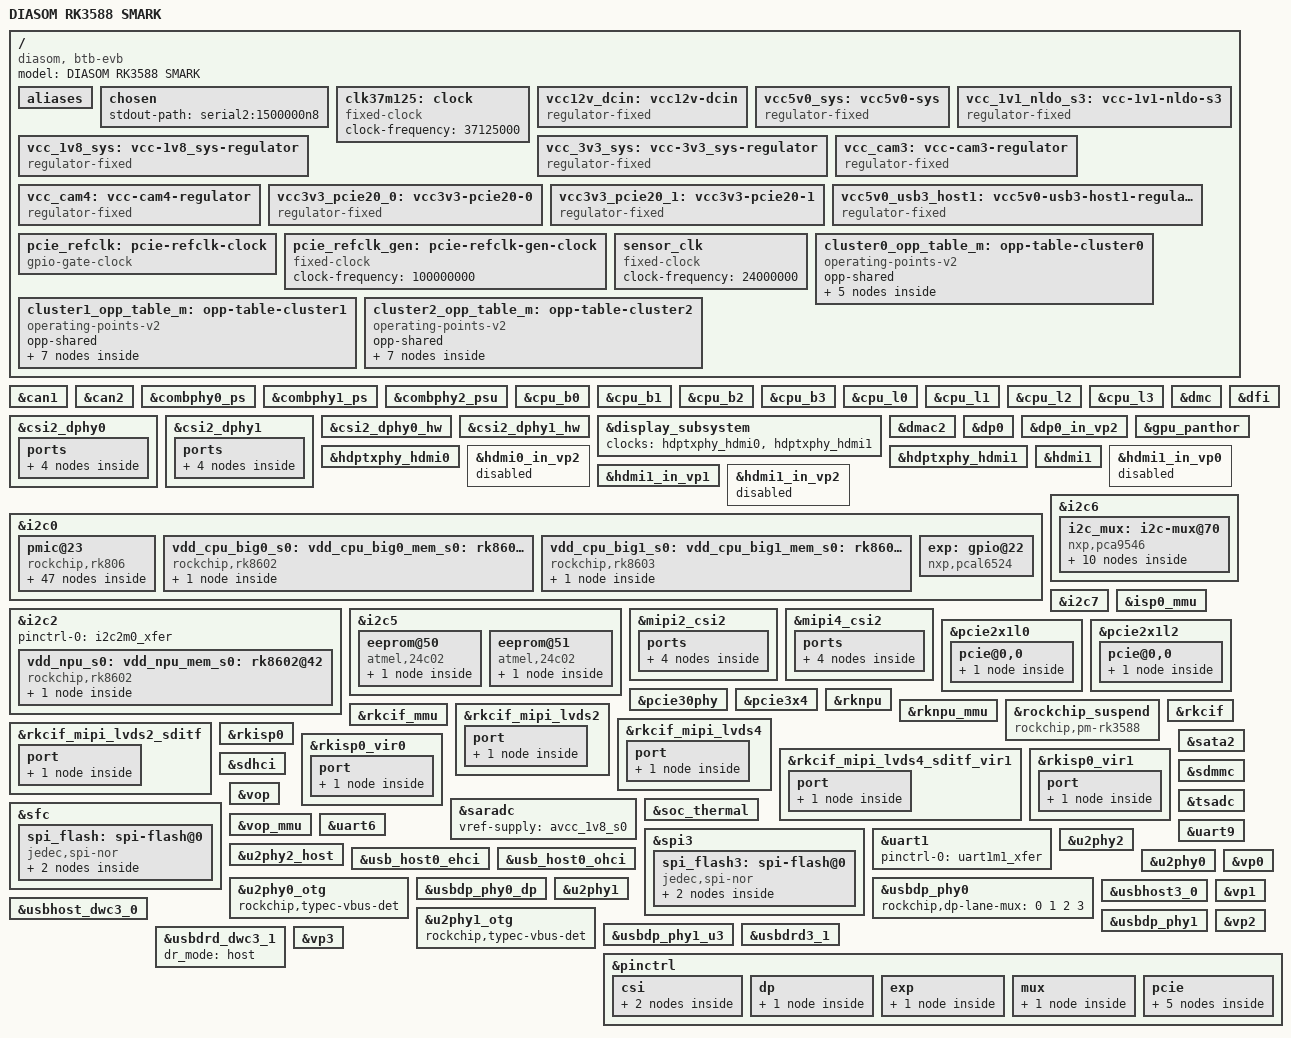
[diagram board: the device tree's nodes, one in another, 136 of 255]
// SPDX-License-Identifier: (GPL-2.0+ OR MIT)
/*
 * Copyright (c) 2022 Rockchip Electronics Co., Ltd.
 * Copyright (c) 2022 Radxa Limited
 *
 */

/dts-v1/;

#include <dt-bindings/gpio/gpio.h>
#include <dt-bindings/leds/common.h>
#include <dt-bindings/pwm/pwm.h>
#include <dt-bindings/pinctrl/rockchip.h>
#include <dt-bindings/input/rk-input.h>
#include <dt-bindings/display/drm_mipi_dsi.h>
#include <dt-bindings/display/media-bus-format.h>
#include <dt-bindings/display/rockchip_vop.h>
#include <dt-bindings/sensor-dev.h>
#include "dt-bindings/usb/pd.h"
#include "rk3588.dtsi"
#include "rk3588-linux.dtsi"

/ {
	model = "DIASOM RK3588 SMARK";
	compatible = "diasom, btb-evb", "rockchip,rk3588";

	aliases {
		ethernet0 = &ethernet0;
		ethernet1 = &ethernet1;
		i2c9 = &i2c9;
		i2c10 = &i2c10;
		i2c11 = &i2c11;
		i2c12 = &i2c12;
		mmc0 = &sdhci;
		mmc1 = &sdmmc;
	};

	chosen {
		stdout-path = "serial2:1500000n8";
	};

	clk37m125: clock {
		compatible = "fixed-clock";
		#clock-cells = <0>;
		clock-frequency = <37125000>;
	};

	vcc12v_dcin: vcc12v-dcin {
		compatible = "regulator-fixed";
		regulator-name = "vcc12v_dcin";
		regulator-always-on;
		regulator-boot-on;
		regulator-min-microvolt = <12000000>;
		regulator-max-microvolt = <12000000>;
	};

	vcc5v0_sys: vcc5v0-sys {
		compatible = "regulator-fixed";
		regulator-name = "vcc5v0_sys";
		regulator-always-on;
		regulator-boot-on;
		regulator-min-microvolt = <5000000>;
		regulator-max-microvolt = <5000000>;
		vin-supply = <&vcc12v_dcin>;
	};

	vcc_1v1_nldo_s3: vcc-1v1-nldo-s3 {
		compatible = "regulator-fixed";
		regulator-name = "vcc_1v1_nldo_s3";
		regulator-always-on;
		regulator-boot-on;
		regulator-min-microvolt = <1100000>;
		regulator-max-microvolt = <1100000>;
		vin-supply = <&vcc5v0_sys>;
	};

	vcc_1v8_sys: vcc-1v8_sys-regulator {
		compatible = "regulator-fixed";
		regulator-name = "vcc_1v8_sys";
		regulator-always-on;
		regulator-boot-on;
		regulator-min-microvolt = <1800000>;
		regulator-max-microvolt = <1800000>;
		vin-supply = <&vcc5v0_sys>;
	};

	vcc_3v3_sys: vcc-3v3_sys-regulator {
		compatible = "regulator-fixed";
		regulator-name = "vcc_3v3_sys";
		regulator-always-on;
		regulator-boot-on;
		regulator-min-microvolt = <3300000>;
		regulator-max-microvolt = <3300000>;
		vin-supply = <&vcc12v_dcin>;
	};

	vcc_cam3: vcc-cam3-regulator {
		pinctrl-names = "default";
		pinctrl-0 = <&cam3_pwr>;
		compatible = "regulator-fixed";
		regulator-boot-on;
		regulator-always-on;
		enable-active-high;
		gpio = <&gpio3 RK_PC1 GPIO_ACTIVE_HIGH>;
		regulator-name = "vcc_cam3";
		startup-delay-us = <250000>;
	};
	
	vcc_cam4: vcc-cam4-regulator {
		pinctrl-names = "default";
		pinctrl-0 = <&cam4_pwr>;
		compatible = "regulator-fixed";
		regulator-boot-on;
		regulator-always-on;
		enable-active-high;
		gpio = <&gpio3 RK_PC2 GPIO_ACTIVE_HIGH>;
		regulator-name = "vcc_cam4";
		startup-delay-us = <250000>;
	};

	vcc3v3_pcie20_0: vcc3v3-pcie20-0 {
		pinctrl-names = "default";
		pinctrl-0 = <&pcie20_0_vcc_pins>;
		compatible = "regulator-fixed";
		regulator-name = "vcc3v3_pcie20_0";
		regulator-min-microvolt = <3300000>;
		regulator-max-microvolt = <3300000>;
		enable-active-high;
		gpios = <&gpio1 RK_PC0 GPIO_ACTIVE_HIGH>;
		startup-delay-us = <5000>;
		vin-supply = <&vcc_3v3_sys>;
	};

	vcc3v3_pcie20_1: vcc3v3-pcie20-1 {
		pinctrl-names = "default";
		pinctrl-0 = <&pcie20_1_vcc_pins>;
		compatible = "regulator-fixed";
		regulator-name = "vcc3v3_pcie20_1";
		regulator-min-microvolt = <3300000>;
		regulator-max-microvolt = <3300000>;
		enable-active-high;
		regulator-always-on;
		regulator-boot-on;
		gpios = <&gpio1 RK_PC1 GPIO_ACTIVE_HIGH>;
		startup-delay-us = <5000>;
		vin-supply = <&vcc_3v3_sys>;
	};

	vcc5v0_usb3_host1: vcc5v0-usb3-host1-regulator {
		compatible = "regulator-fixed";
		regulator-name = "vcc5v0_usb3_host1";
		regulator-boot-on;
		regulator-always-on;
		regulator-min-microvolt = <5000000>;
		regulator-max-microvolt = <5000000>;
		vin-supply = <&vcc12v_dcin>;
	};

	pcie_refclk: pcie-refclk-clock {
		pinctrl-names = "default";
		pinctrl-0 = <&pcie30_clk_pins>;
		compatible = "gpio-gate-clock";
		clocks = <&pcie_refclk_gen>;
		#clock-cells = <0>;
		enable-gpios = <&gpio4 RK_PA5 GPIO_ACTIVE_HIGH>;
	};

	pcie_refclk_gen: pcie-refclk-gen-clock {
		compatible = "fixed-clock";
		#clock-cells = <0>;
		clock-frequency = <100000000>;
	};

	sensor_clk: sensor_clk {
        compatible = "fixed-clock";
        #clock-cells = <0>;
        clock-frequency = <24000000>;
    };

	cluster0_opp_table_m: opp-table-cluster0 {
		compatible = "operating-points-v2";
		opp-shared;

		opp-1008000000 {
			opp-hz = /bits/ 64 <1008000000>;
			opp-microvolt = <675000 675000 950000>;
			clock-latency-ns = <40000>;
		};
		opp-1200000000 {
			opp-hz = /bits/ 64 <1200000000>;
			opp-microvolt = <712500 712500 950000>;
			clock-latency-ns = <40000>;
		};
		opp-1416000000 {
			opp-hz = /bits/ 64 <1416000000>;
			opp-microvolt = <762500 762500 950000>;
			clock-latency-ns = <40000>;
			opp-suspend;
		};
		opp-1608000000 {
			opp-hz = /bits/ 64 <1608000000>;
			opp-microvolt = <850000 850000 950000>;
			clock-latency-ns = <40000>;
		};
		opp-1800000000 {
			opp-hz = /bits/ 64 <1800000000>;
			opp-microvolt = <950000 950000 950000>;
			clock-latency-ns = <40000>;
		};
	};

	cluster1_opp_table_m: opp-table-cluster1 {
		compatible = "operating-points-v2";
		opp-shared;

		opp-1200000000 {
			opp-hz = /bits/ 64 <1200000000>;
			opp-microvolt = <675000 675000 1000000>;
			clock-latency-ns = <40000>;
		};
		opp-1416000000 {
			opp-hz = /bits/ 64 <1416000000>;
			opp-microvolt = <725000 725000 1000000>;
			clock-latency-ns = <40000>;
		};
		opp-1608000000 {
			opp-hz = /bits/ 64 <1608000000>;
			opp-microvolt = <762500 762500 1000000>;
			clock-latency-ns = <40000>;
		};
		opp-1800000000 {
			opp-hz = /bits/ 64 <1800000000>;
			opp-microvolt = <850000 850000 1000000>;
			clock-latency-ns = <40000>;
		};
		opp-2016000000 {
			opp-hz = /bits/ 64 <2016000000>;
			opp-microvolt = <925000 925000 1000000>;
			clock-latency-ns = <40000>;
		};
		opp-2208000000 {
			opp-hz = /bits/ 64 <2208000000>;
			opp-microvolt = <987500 987500 1000000>;
			clock-latency-ns = <40000>;
		};
		opp-2400000000 {
			opp-hz = /bits/ 64 <2400000000>;
			opp-microvolt = <1000000 1000000 1000000>;
			clock-latency-ns = <40000>;
		};
	};

	cluster2_opp_table_m: opp-table-cluster2 {
		compatible = "operating-points-v2";
		opp-shared;

		opp-1200000000 {
			opp-hz = /bits/ 64 <1200000000>;
			opp-microvolt = <675000 675000 1000000>;
			clock-latency-ns = <40000>;
		};
		opp-1416000000 {
			opp-hz = /bits/ 64 <1416000000>;
			opp-microvolt = <725000 725000 1000000>;
			clock-latency-ns = <40000>;
		};
		opp-1608000000 {
			opp-hz = /bits/ 64 <1608000000>;
			opp-microvolt = <762500 762500 1000000>;
			clock-latency-ns = <40000>;
		};
		opp-1800000000 {
			opp-hz = /bits/ 64 <1800000000>;
			opp-microvolt = <850000 850000 1000000>;
			clock-latency-ns = <40000>;
		};
		opp-2016000000 {
			opp-hz = /bits/ 64 <2016000000>;
			opp-microvolt = <925000 925000 1000000>;
			clock-latency-ns = <40000>;
		};
		opp-2208000000 {
			opp-hz = /bits/ 64 <2208000000>;
			opp-microvolt = <987500 987500 1000000>;
			clock-latency-ns = <40000>;
		};
		opp-2400000000 {
			opp-hz = /bits/ 64 <2400000000>;
			opp-microvolt = <1000000 1000000 1000000>;
			clock-latency-ns = <40000>;
		};
	};
};

&can1 {
	status = "okay";
	pinctrl-names = "default";
	pinctrl-0 = <&can1m1_pins>;
	assigned-clocks = <&cru CLK_CAN1>;
	assigned-clock-rates = <200000000>;
};

&can2 {
	status = "okay";
	pinctrl-names = "default";
	pinctrl-0 = <&can2m1_pins>;
	assigned-clocks = <&cru CLK_CAN2>;
	assigned-clock-rates = <200000000>;
};

&combphy0_ps {
	/* pcie2x1l2 (PCIE20_0) */
	status = "okay";
};

&combphy1_ps {
	/* pcie2x1l0 (PCIE20_1) */
	status = "okay";
};

&combphy2_psu {
	status = "okay";
};

&cpu_b0 {
	cpu-supply = <&vdd_cpu_big0_s0>;
	// mem-supply = <&vdd_cpu_big0_s0>;
	operating-points-v2 = <&cluster1_opp_table_m>;
};

&cpu_b1 {
	cpu-supply = <&vdd_cpu_big0_s0>;
	// mem-supply = <&vdd_cpu_big0_s0>;
	operating-points-v2 = <&cluster1_opp_table_m>;
};

&cpu_b2 {
	cpu-supply = <&vdd_cpu_big1_s0>;
	// mem-supply = <&vdd_cpu_big1_s0>;
	operating-points-v2 = <&cluster2_opp_table_m>;
};

&cpu_b3 {
	cpu-supply = <&vdd_cpu_big1_s0>;
	// mem-supply = <&vdd_cpu_big1_s0>;
	operating-points-v2 = <&cluster2_opp_table_m>;
};

&cpu_l0 {
	cpu-supply = <&vdd_cpu_lit_s0>;
	// mem-supply = <&vdd_cpu_lit_s0>;
	operating-points-v2 = <&cluster0_opp_table_m>;
};

&cpu_l1 {
	cpu-supply = <&vdd_cpu_lit_s0>;
	// mem-supply = <&vdd_cpu_lit_s0>;
	operating-points-v2 = <&cluster0_opp_table_m>;
};

&cpu_l2 {
	cpu-supply = <&vdd_cpu_lit_s0>;
	// mem-supply = <&vdd_cpu_lit_s0>;
	operating-points-v2 = <&cluster0_opp_table_m>;
};

&cpu_l3 {
	cpu-supply = <&vdd_cpu_lit_s0>;
	// mem-supply = <&vdd_cpu_lit_s0>;
	operating-points-v2 = <&cluster0_opp_table_m>;
};

&csi2_dphy0 {
	status = "okay";

	ports {
		#address-cells = <1>;
		#size-cells = <0>;

		port@0 {
			reg = <0>;
			#address-cells = <1>;
			#size-cells = <0>;

			mipidphy0_in_ucam0: endpoint@1 {
				reg = <1>;
				remote-endpoint = <&imx415_i2c11_out>;
				data-lanes = <1 2 3 4>;
			};
		};

		port@1 {
			reg = <1>;
			#address-cells = <1>;
			#size-cells = <0>;

			csidphy0_out: endpoint@0 {
				reg = <0>;
				remote-endpoint = <&mipi2_csi2_input>;
			};
		};
	};
};


&csi2_dphy1 {
	status = "okay";

	ports {
		#address-cells = <1>;
		#size-cells = <0>;

		port@0 {
			reg = <0>;
			#address-cells = <1>;
			#size-cells = <0>;

			mipidphy1_in_ucam1: endpoint@1 {
				reg = <1>;
				remote-endpoint = <&imx415_i2c12_out>;
				data-lanes = <1 2 3 4>;
			};
		};

		port@1 {
			reg = <1>;
			#address-cells = <1>;
			#size-cells = <0>;

			csidphy1_out: endpoint@0 {
				reg = <0>;
				remote-endpoint = <&mipi4_csi2_input>;
			};
		};
	};
};

&csi2_dphy0_hw {
	status = "okay";
};

&csi2_dphy1_hw {
	status = "okay";
};

&display_subsystem {
	clocks = <&hdptxphy_hdmi0>, <&hdptxphy_hdmi1>;
	clock-names = "hdmi0_phy_pll", "hdmi1_phy_pll";
};

&dmc {
	center-supply = <&vdd_ddr_s0>;
	mem-supply = <&vdd_log_s0>;
	status = "okay";
};

&dfi {
	status = "okay";
};

&dmac2 {
	status = "okay";
};

&dp0 {
	pinctrl-names = "default";
	pinctrl-0 = <&dp0_tx1_hpd>;
	hpd-gpios = <&gpio2 RK_PC1 GPIO_ACTIVE_HIGH>;
	status = "okay";
};

&dp0_in_vp2 {
	status = "okay";
};

&gpu_panthor {
	mali-supply = <&vdd_gpu_s0>;
	mem-supply = <&vdd_gpu_mem_s0>;
	status = "okay";
};

&hdptxphy_hdmi0 {
	status = "okay";
};

&hdptxphy_hdmi1 {
	status = "okay";
};

&hdmi0_in_vp2 {
	status = "disabled";
};

&hdmi1 {
	status = "okay";
	pinctrl-names = "default";
	pinctrl-0 = <&hdmim0_tx1_hpd>;
    cec-enable = "true";
};

&hdmi1_in_vp0 {
	status = "disabled";
};

&hdmi1_in_vp1 {
	status = "okay";
};

&hdmi1_in_vp2 {
	status = "disabled";
};

&i2c0 {
	status = "okay";
	pinctrl-names = "default";
	pinctrl-0 = <&i2c0m2_xfer>;
	clock-frequency = <100000>;

	pmic@23 {
		compatible = "rockchip,rk806";
		reg = <0x23>;
		interrupt-parent = <&gpio0>;
		interrupts = <7 IRQ_TYPE_LEVEL_LOW>;
		pinctrl-names = "default", "pmic-power-off";
		pinctrl-0 = <&pmic_pins>, <&rk806_dvs1_null>, <&rk806_dvs2_null>, <&rk806_dvs3_null>;
		pinctrl-1 = <&rk806_dvs1_pwrdn>;

		/* 2800mv-3500mv */
		low_voltage_threshold = <3000>;
		/* 2700mv-3400mv */
		shutdown_voltage_threshold = <2700>;
		/* 140 160 */
		shutdown_temperture_threshold = <160>;
		hotdie_temperture_threshold = <115>;

		shutdown-sequence = <2 2 2 0 2 0 2 1 1 2
					2 2 2 2 2
					1 0 0 0 0 2>;

		/* low power forced shutdown sequence */
		vb-shutdown-sequence = <2 2 2 0 2 0 2 0 0 2
					2 2 2 2 2
					0 0 0 0 0 2>;

		pwron-on-time-500ms;
		/* 0: restart PMU;
		 * 1: reset all the power off reset registers,
		 *    forcing the state to switch to ACTIVE mode;
		 * 2: Reset all the power off reset registers,
		 *    forcing the state to switch to ACTIVE mode,
		 *    and simultaneously pull down the RESETB PIN for 5mS before releasing
		 */
		pmic-reset-func = <1>;

		buck5-feedback-disable;

		vcc1-supply = <&vcc5v0_sys>;
		vcc2-supply = <&vcc5v0_sys>;
		vcc3-supply = <&vcc5v0_sys>;
		vcc4-supply = <&vcc5v0_sys>;
		vcc5-supply = <&vcc5v0_sys>;
		vcc6-supply = <&vcc5v0_sys>;
		vcc7-supply = <&vcc5v0_sys>;
		vcc8-supply = <&vcc5v0_sys>;
		vcc9-supply = <&vcc5v0_sys>;
		vcc10-supply = <&vcc5v0_sys>;
		vcc11-supply = <&vcc_2v0_pldo_s3>;
		vcc12-supply = <&vcc5v0_sys>;
		vcc13-supply = <&vcc_1v1_nldo_s3>;
		vcc14-supply = <&vcc_1v1_nldo_s3>;
		vcca-supply = <&vcc5v0_sys>;

		rk806_dvs1_null: dvs1-null-pins {
			pins = "gpio_pwrctrl1";
			function = "pin_fun0";
		};

		rk806_dvs2_null: dvs2-null-pins {
			pins = "gpio_pwrctrl2";
			function = "pin_fun0";
		};

		rk806_dvs3_null: dvs3-null-pins {
			pins = "gpio_pwrctrl3";
			function = "pin_fun0";
		};

		rk806_dvs1_pwrdn: rk806_dvs1_pwrdn {
			pins = "gpio_pwrctrl1";
			function = "pin_fun2";
		};

		regulators {
			vdd_gpu_s0: vdd_gpu_mem_s0: DCDC_REG1 {
				regulator-boot-on;
				regulator-min-microvolt = <550000>;
				regulator-max-microvolt = <950000>;
				regulator-ramp-delay = <12500>;
				regulator-name = "vdd_gpu_s0";
				regulator-enable-ramp-delay = <400>;
				regulator-state-mem {
					regulator-off-in-suspend;
				};
			};

			vdd_cpu_lit_s0: vdd_cpu_lit_mem_s0: DCDC_REG2 {
				regulator-always-on;
				regulator-boot-on;
				regulator-init-microvolt = <800000>;
				regulator-min-microvolt = <550000>;
				regulator-max-microvolt = <950000>;
				regulator-ramp-delay = <12500>;
				regulator-name = "vdd_cpu_lit_s0";
				regulator-state-mem {
					regulator-off-in-suspend;
				};
			};

			vdd_log_s0: DCDC_REG3 {
				regulator-always-on;
				regulator-boot-on;
				regulator-min-microvolt = <675000>;
				regulator-max-microvolt = <800000>;
				regulator-ramp-delay = <12500>;
				regulator-name = "vdd_log_s0";
				regulator-state-mem {
					regulator-off-in-suspend;
					regulator-suspend-microvolt = <750000>;
				};
			};

			vdd_vdenc_s0: vdd_vdenc_mem_s0: DCDC_REG4 {
				regulator-always-on;
				regulator-boot-on;
				regulator-min-microvolt = <550000>;
				regulator-max-microvolt = <950000>;
				regulator-init-microvolt = <750000>;
				regulator-ramp-delay = <12500>;
				regulator-name = "vdd_vdenc_s0";
				regulator-state-mem {
					regulator-off-in-suspend;
				};
			};

			vdd_ddr_s0: DCDC_REG5 {
				regulator-always-on;
				regulator-boot-on;
				regulator-min-microvolt = <675000>;
				regulator-max-microvolt = <900000>;
				regulator-ramp-delay = <12500>;
				regulator-name = "vdd_ddr_s0";
				regulator-state-mem {
					regulator-off-in-suspend;
					regulator-suspend-microvolt = <850000>;
				};
			};

			vdd2_ddr_s3: DCDC_REG6 {
				regulator-always-on;
				regulator-boot-on;
				regulator-name = "vdd2_ddr_s3";
				regulator-state-mem {
					regulator-on-in-suspend;
				};
			};

			vcc_2v0_pldo_s3: DCDC_REG7 {
				regulator-always-on;
				regulator-boot-on;
				regulator-min-microvolt = <2000000>;
				regulator-max-microvolt = <2000000>;
				regulator-name = "vdd_2v0_pldo_s3";
				regulator-state-mem {
					regulator-on-in-suspend;
					regulator-suspend-microvolt = <2000000>;
				};
			};

			vcc_3v3_s3: DCDC_REG8 {
				regulator-always-on;
				regulator-boot-on;
				regulator-min-microvolt = <3300000>;
				regulator-max-microvolt = <3300000>;
				regulator-name = "vcc_3v3_s3";
				regulator-state-mem {
					regulator-on-in-suspend;
					regulator-suspend-microvolt = <3300000>;
				};
			};

			vddq_ddr_s0: DCDC_REG9 {
				regulator-always-on;
				regulator-boot-on;
				regulator-name = "vddq_ddr_s0";
				regulator-state-mem {
					regulator-off-in-suspend;
				};
			};

			vcc_1v8_s3: DCDC_REG10 {
				regulator-always-on;
				regulator-boot-on;
				regulator-min-microvolt = <1800000>;
				regulator-max-microvolt = <1800000>;
				regulator-name = "vcc_1v8_s3";
				regulator-state-mem {
					regulator-on-in-suspend;
					regulator-suspend-microvolt = <1800000>;
				};
			};

			avcc_1v8_s0: PLDO_REG1 {
				regulator-always-on;
				regulator-boot-on;
				regulator-min-microvolt = <1800000>;
				regulator-max-microvolt = <1800000>;
				regulator-name = "avcc_1v8_s0";
				regulator-state-mem {
					regulator-off-in-suspend;
				};
			};

			vcc_1v8_s0: PLDO_REG2 {
				regulator-always-on;
				regulator-boot-on;
				regulator-min-microvolt = <1800000>;
				regulator-max-microvolt = <1800000>;
				regulator-name = "vcc_1v8_s0";
				regulator-state-mem {
					regulator-off-in-suspend;
					regulator-suspend-microvolt = <1800000>;
				};
			};

			avdd_1v2_s0: PLDO_REG3 {
				regulator-always-on;
				regulator-boot-on;
				regulator-min-microvolt = <1200000>;
				regulator-max-microvolt = <1200000>;
				regulator-name = "avdd_1v2_s0";
				regulator-state-mem {
					regulator-off-in-suspend;
				};
			};

			vcc_3v3_s0: PLDO_REG4 {
				regulator-always-on;
				regulator-boot-on;
				regulator-min-microvolt = <3300000>;
				regulator-max-microvolt = <3300000>;
				regulator-name = "vcc_3v3_s0";
				regulator-state-mem {
					regulator-off-in-suspend;
				};
			};

			vccio_sd_s0: PLDO_REG5 {
				regulator-always-on;
				regulator-boot-on;
				regulator-min-microvolt = <1800000>;
				regulator-max-microvolt = <3300000>;
				regulator-name = "vccio_sd_s0";
				regulator-state-mem {
					regulator-off-in-suspend;
				};
			};

			pldo6_s3: PLDO_REG6 {
				regulator-always-on;
				regulator-boot-on;
				regulator-min-microvolt = <1800000>;
				regulator-max-microvolt = <1800000>;
				regulator-name = "pldo6_s3";
				regulator-state-mem {
					regulator-on-in-suspend;
					regulator-suspend-microvolt = <1800000>;
				};
			};

			vdd_0v75_s3: NLDO_REG1 {
				regulator-always-on;
				regulator-boot-on;
				regulator-min-microvolt = <750000>;
				regulator-max-microvolt = <750000>;
				regulator-name = "vdd_0v75_s3";
				regulator-state-mem {
					regulator-on-in-suspend;
					regulator-suspend-microvolt = <750000>;
				};
			};

			vdd_ddr_pll_s0: NLDO_REG2 {
				regulator-always-on;
				regulator-boot-on;
				regulator-min-microvolt = <850000>;
				regulator-max-microvolt = <850000>;
				regulator-name = "vdd_ddr_pll_s0";
				regulator-state-mem {
					regulator-off-in-suspend;
					regulator-suspend-microvolt = <850000>;
				};
			};

			avdd_0v75_s0: NLDO_REG3 {
				regulator-always-on;
				regulator-boot-on;
				regulator-min-microvolt = <837500>;
				regulator-max-microvolt = <837500>;
				regulator-name = "avdd_0v75_s0";
				regulator-state-mem {
					regulator-off-in-suspend;
				};
			};

			vdd_0v85_s0: NLDO_REG4 {
				regulator-always-on;
				regulator-boot-on;
				regulator-min-microvolt = <850000>;
				regulator-max-microvolt = <850000>;
				regulator-name = "vdd_0v85_s0";
				regulator-state-mem {
					regulator-off-in-suspend;
				};
			};

			vdd_0v75_s0: NLDO_REG5 {
				regulator-always-on;
				regulator-boot-on;
				regulator-min-microvolt = <750000>;
				regulator-max-microvolt = <750000>;
				regulator-name = "vdd_0v75_s0";
				regulator-state-mem {
					regulator-off-in-suspend;
				};
			};
		};
	};

	vdd_cpu_big0_s0: vdd_cpu_big0_mem_s0: rk8602@42 {
		compatible = "rockchip,rk8602";
		reg = <0x42>;
		vin-supply = <&vcc5v0_sys>;
		regulator-compatible = "rk860x-reg";
		regulator-name = "vdd_cpu_big0_s0";
		regulator-min-microvolt = <550000>;
		regulator-max-microvolt = <1050000>;
		regulator-ramp-delay = <2300>;
		rockchip,suspend-voltage-selector = <1>;
		regulator-boot-on;
		regulator-always-on;
		regulator-state-mem {
			regulator-off-in-suspend;
		};
	};

	vdd_cpu_big1_s0: vdd_cpu_big1_mem_s0: rk8603@43 {
		compatible = "rockchip,rk8603";
		reg = <0x43>;
		vin-supply = <&vcc5v0_sys>;
		regulator-compatible = "rk860x-reg";
		regulator-name = "vdd_cpu_big1_s0";
		regulator-min-microvolt = <550000>;
		regulator-max-microvolt = <1050000>;
		regulator-ramp-delay = <2300>;
		rockchip,suspend-voltage-selector = <1>;
		regulator-boot-on;
		regulator-always-on;
		regulator-state-mem {
			regulator-off-in-suspend;
		};
	};

	exp: gpio@22 {
		pinctrl-names = "default";
		pinctrl-0 = <&exp_pins>;
		compatible = "nxp,pcal6524";
		reg = <0x22>;
		gpio-controller;
		#gpio-cells = <2>;
		interrupt-controller;
		#interrupt-cells = <2>;
		interrupt-parent = <&gpio1>;
		interrupts = <RK_PA7 IRQ_TYPE_LEVEL_LOW>;
		vcc-supply = <&pldo6_s3>;
		gpio-line-names =
			/* P0_0-7 */
			"led", "p01", "p02", "p03",
			"p04", "p05", "p06", "p07",
			/* P1_0-7 */
			"p10", "p11", "p12", "",
			"", "", "", "",
			/* P2_0-7 */
			"USB1_EN_OC", "USB1_EN", "USB0_EN_OC", "USB0_EN",
			"", "", "", "";
	};
};

&i2c2 {
	status = "okay";
	pinctrl-names = "default";
	pinctrl-0 = <&i2c2m0_xfer>;

	vdd_npu_s0: vdd_npu_mem_s0: rk8602@42 {
		compatible = "rockchip,rk8602";
		reg = <0x42>;
		vin-supply = <&vcc5v0_sys>;
		regulator-compatible = "rk860x-reg";
		regulator-name = "vdd_npu_s0";
		regulator-min-microvolt = <550000>;
		regulator-max-microvolt = <950000>;
		regulator-ramp-delay = <2300>;
		rockchip,suspend-voltage-selector = <1>;
		regulator-boot-on;
		regulator-always-on;
		regulator-state-mem {
			regulator-off-in-suspend;
		};
	};

	
};

&i2c5 {
	status = "okay";
	clock-frequency = <100000>;
	pinctrl-names = "default";
	pinctrl-0 = <&i2c5m4_xfer>;

	eeprom@50 {
		compatible = "atmel,24c02";
		reg = <0x50>;
		pagesize = <16>;
		vcc-supply = <&vcc_1v8_sys>;

		#address-cells = <1>;
		#size-cells = <1>;

		mac0: mac-address@fa {
			reg = <0xfa 0x06>;
			read-only;
		};
	};

	/* 24aa025e48 */
	eeprom@51 {
		compatible = "atmel,24c02";
		reg = <0x51>;
		pagesize = <16>;
		vcc-supply = <&vcc_1v8_sys>;
		#address-cells = <1>;
		#size-cells = <1>;

		mac1: mac-address@fa {
			reg = <0xfa 0x06>;
		};
	};
};

&i2c6 {
	status = "okay";
	clock-frequency = <100000>;
	pinctrl-names = "default";
	pinctrl-0 = <&i2c6m0_xfer>;

	i2c_mux: i2c-mux@70 {
		pinctrl-0 = <&mux_pins>;
		pinctrl-names = "default";
		compatible = "nxp,pca9546";
		reg = <0x70>;
		i2c-mux-idle-disconnect;
		reset-gpios = <&gpio0 RK_PC6 GPIO_ACTIVE_LOW>;
		vdd-supply = <&vcc_3v3_sys>;
		#address-cells = <1>;
		#size-cells = <0>;

		i2c9: i2c@0 {
			reg = <0>;
			#address-cells = <1>;
			#size-cells = <0>;
		};

		i2c10: i2c@1 {
			reg = <1>;
			#address-cells = <1>;
			#size-cells = <0>;
		};

		i2c11: i2c@2 {
			reg = <2>;
			#address-cells = <1>;
			#size-cells = <0>;

			imx415_i2c11: camera-0@1a {
				compatible = "sony,imx415";
				reg = <0x1a>;
				clocks = <&clk37m125 0>;
				clock-names = "xvclk";
				avdd-supply = <&vcc_cam3>;
				dvdd-supply = <&vcc_cam3>;
				ovdd-supply = <&vcc_cam3>;
				rockchip,camera-module-index = <1>;
				rockchip,camera-module-facing = "back";
				rockchip,camera-module-name = "IMX415";
				rockchip,camera-module-lens-name = "NC";
				status = "okay";

				port {
					imx415_i2c11_out: endpoint {
						data-lanes = <1 2 3 4>;
						remote-endpoint = <&mipidphy0_in_ucam0>;
						link-frequencies = /bits/ 64 <594000000>;
					};
				};
			};
		};

		i2c12: i2c@3 {
			reg = <3>;
			#address-cells = <1>;
			#size-cells = <0>;

			imx415_i2c12: camera-1@1a {
				compatible = "sony,imx415";
				reg = <0x1a>;
				clocks = <&clk37m125 0>;
				clock-names = "xvclk";
				avdd-supply = <&vcc_cam4>;
				dvdd-supply = <&vcc_cam4>;
				ovdd-supply = <&vcc_cam4>;
				rockchip,camera-module-index = <1>;
				rockchip,camera-module-facing = "back";
				rockchip,camera-module-name = "IMX415";
				rockchip,camera-module-lens-name = "NC";
				status = "okay";

				port {
					imx415_i2c12_out: endpoint {
						data-lanes = <1 2 3 4>;
						remote-endpoint = <&mipidphy1_in_ucam1>;
						link-frequencies = /bits/ 64 <594000000>;
					};
				};
			};
		};
	};
};

&i2c7 {
	status = "okay";
	clock-frequency = <100000>;
	pinctrl-names = "default";
	pinctrl-0 = <&i2c7m0_xfer>;
};

&isp0_mmu {
	status = "okay";
};

&mipi2_csi2 {
	status = "okay";

	ports {
		#address-cells = <1>;
		#size-cells = <0>;

		port@0 {
			reg = <0>;
			#address-cells = <1>;
			#size-cells = <0>;

			mipi2_csi2_input: endpoint@1 {
				reg = <1>;
				remote-endpoint = <&csidphy0_out>;
			};
		};

		port@1 {
			reg = <1>;
			#address-cells = <1>;
			#size-cells = <0>;

			mipi2_csi2_output: endpoint@0 {
				reg = <0>;
				remote-endpoint = <&cif_mipi2_in0>;
			};
		};
	};
};

&mipi4_csi2 {
	status = "okay";

	ports {
		#address-cells = <1>;
		#size-cells = <0>;

		port@0 {
			reg = <0>;
			#address-cells = <1>;
			#size-cells = <0>;

			mipi4_csi2_input: endpoint@1 {
				reg = <1>;
				remote-endpoint = <&csidphy1_out>;
			};
		};

		port@1 {
			reg = <1>;
			#address-cells = <1>;
			#size-cells = <0>;

			mipi4_csi2_output: endpoint@0 {
				reg = <0>;
				remote-endpoint = <&cif_mipi2_in4>;
			};
		};
	};
};

&pcie2x1l0 {
	/* PCIE20_1 */
	pinctrl-0 = <&pcie20x1_pins>;
	reset-gpios = <&gpio1 RK_PB4 GPIO_ACTIVE_HIGH>;
	vpcie3v3-supply = <&vcc3v3_pcie20_1>;
	status = "okay";

	pcie@0,0 {
		reg = <0x200000 0 0 0 0>;
		ranges;
		device_type = "pci";
		bus-range = <0x20 0x2f>;
		#address-cells = <3>;
		#size-cells = <2>;

		ethernet0: ethernet@0,0 {
			/* RTL8125BI-CG DD12 */
			compatible = "pci10ec,8125";
			reg = <0x210000 0 0 0 0>;
			nvmem-cells = <&mac0>;
			nvmem-cell-names = "mac-address";
		};
	};
};

&pcie2x1l2 {
	/* PCIE20_0 */
	reset-gpios = <&gpio3 RK_PD1 GPIO_ACTIVE_HIGH>;
	vpcie3v3-supply = <&vcc3v3_pcie20_0>;
	status = "okay";

	pcie@0,0 {
		reg = <0x400000 0 0 0 0>;
		ranges;
		device_type = "pci";
		bus-range = <0x40 0x4f>;
		#address-cells = <3>;
		#size-cells = <2>;

		ethernet1: ethernet@0,0 {
			/* RTL8125BI-CG DD8 */
			compatible = "pci10ec,8125";
			reg = <0x410000 0 0 0 0>;
			nvmem-cells = <&mac1>;
			nvmem-cell-names = "mac-address";
		};
	};
};

&pcie30phy {
	status = "okay";
};

&pcie3x4 {
	pinctrl-names = "default";
	pinctrl-0 = <&pcie30x4m3_pins>;
	clocks = <&cru ACLK_PCIE_4L_MSTR>, <&cru ACLK_PCIE_4L_SLV>,
		 <&cru ACLK_PCIE_4L_DBI>, <&cru PCLK_PCIE_4L>,
		  <&cru CLK_PCIE_AUX0>, <&cru CLK_PCIE4L_PIPE>,
		 <&pcie_refclk>;
	clock-names = "aclk_mst", "aclk_slv",
		      "aclk_dbi", "pclk",
		      "aux", "pipe",
		      "ref";
	vpcie3v3-supply = <&vcc_3v3_sys>;
	status = "okay";
};

&rknpu {
	rknpu-supply = <&vdd_npu_s0>;
	mem-supply = <&vdd_npu_mem_s0>;
	status = "okay";
};

&rknpu_mmu {
	status = "okay";
};

&rockchip_suspend {
	compatible = "rockchip,pm-rk3588";
	status = "okay";
	rockchip,sleep-debug-en = <1>;
	rockchip,sleep-mode-config = <
		(0
		| RKPM_SLP_ARMOFF_DDRPD
		)
	>;
	rockchip,wakeup-config = <
		(0
		| RKPM_GPIO_WKUP_EN
		| RKPM_USB_WKUP_EN
		)
	>;
};

&rkcif {
    status = "okay";
};

&rkcif_mmu {
    status = "okay";
};

&rkcif_mipi_lvds2 {
	status = "okay";

	port {
		cif_mipi2_in0: endpoint {
			remote-endpoint = <&mipi2_csi2_output>;
		};
	};
};

&rkcif_mipi_lvds4 {
	status = "okay";

	port {
		cif_mipi2_in4: endpoint {
			remote-endpoint = <&mipi4_csi2_output>;
		};
	};
};


&rkcif_mipi_lvds2_sditf {
	status = "okay";
	port {
		mipi_lvds2_sditf: endpoint {
			remote-endpoint = <&isp0_vir0>;
		};
	};
};

&rkcif_mipi_lvds4_sditf_vir1 {
	status = "okay";
	port {
		mipi_lvds4_sditf_vir1: endpoint {
			remote-endpoint = <&isp0_vir1>;
		};
	};
};

&rkisp0 {
	status = "okay";
};

&rkisp0_vir0 {
	status = "okay";
	port {
		#address-cells = <1>;
		#size-cells = <0>;

		isp0_vir0: endpoint@0 {
			reg = <0>;
			remote-endpoint = <&mipi_lvds2_sditf>;
		};
	};
};

&rkisp0_vir1 {
	status = "okay";
	port {
		#address-cells = <1>;
		#size-cells = <0>;

		isp0_vir1: endpoint@0 {
			reg = <0>;
			remote-endpoint = <&mipi_lvds4_sditf_vir1>;
		};
	};
};


&saradc {
	status = "okay";
	vref-supply = <&avcc_1v8_s0>;
};

&sata2 {
	status = "okay";
};

&sdhci {
	bus-width = <8>;
	no-sdio;
	no-sd;
	non-removable;
	max-frequency = <200000000>;
	mmc-hs400-1_8v;
	mmc-hs400-enhanced-strobe;
	status = "okay";
};

&sdmmc {
	max-frequency = <200000000>;
	no-sdio;
	no-mmc;
	bus-width = <4>;
	cap-mmc-highspeed;
	cap-sd-highspeed;
	disable-wp;
	sd-uhs-sdr104;
	vmmc-supply = <&vcc_3v3_s3>;
	vqmmc-supply = <&vccio_sd_s0>;
	pinctrl-names = "default";
	pinctrl-0 = <&sdmmc_bus4 &sdmmc_clk &sdmmc_cmd &sdmmc_det>;
	status = "okay";
};

&sfc {
	status = "okay";
	max-freq = <50000000>;
	#address-cells = <1>;
	#size-cells = <0>;
	pinctrl-names = "default";
	pinctrl-0 = <&fspim1_pins>;

	spi_flash: spi-flash@0 {
		#address-cells = <1>;
		#size-cells = <0>;
		compatible = "jedec,spi-nor";
		reg = <0x0>;
		spi-max-frequency = <50000000>;
		spi-tx-bus-width = <1>;
		spi-rx-bus-width = <4>;
		status = "okay";

		partitions {
			compatible = "fixed-partitions";
			#address-cells = <1>;
			#size-cells = <1>;

			loader@0 {
				label = "loader";
				reg = <0x0 0x1000000>;
			};
		};
	};
};

&soc_thermal {
	status = "okay";
};

&spi3 {
	pinctrl-0 = <&spi3m0_pins &spi3m0_cs0>;
	pinctrl-names = "default";
	num-cs = <2>;
	status = "okay";

	spi_flash3: spi-flash@0 {
		#address-cells = <1>;
		#size-cells = <0>;
		compatible = "jedec,spi-nor";
		reg = <0x0>;
		spi-max-frequency = <50000000>;
		spi-tx-bus-width = <1>;
		spi-rx-bus-width = <1>;
		status = "okay";

		partitions {
			compatible = "fixed-partitions";
			#address-cells = <1>;
			#size-cells = <1>;

			loader@0 {
				label = "loader";
				reg = <0x0 0x1000000>;
			};
		};
	};
};


&tsadc {
	status = "okay";
};

&vop {
	status = "okay";
};

&vop_mmu {
	status = "okay";
};

&uart1 {
	pinctrl-0 = <&uart1m1_xfer>;
	status = "okay";
};

&uart6 {
	pinctrl-0 = <&uart6m1_xfer &uart6m1_ctsn &uart6m1_rtsn>;
	status = "okay";
};

&uart9 {
	pinctrl-0 = <&uart9m2_xfer &uart9m2_ctsn &uart9m2_rtsn>;
	status = "okay";
};


/*USB2.0 HOST0*/
&u2phy2 {
	status = "okay";
};

&u2phy2_host {
	status = "okay";
};

&usb_host0_ehci {
	status = "okay";
};

&usb_host0_ohci {
	status = "okay";
};

/*USB3.0 OTG0 type C*/

&u2phy0 {
	status = "okay";
};

&u2phy0_otg {
	rockchip,typec-vbus-det;
	status = "okay";
};

&usbdp_phy0 {
	rockchip,dp-lane-mux = <0 1 2 3>;
	status = "okay";
};

&usbdp_phy0_dp {
	status = "okay";
};

/**/
&usbhost3_0 {
	status = "okay";
};

&usbhost_dwc3_0 {
	status = "okay";
};

/*USB3.0 OTG1 type C*/
&u2phy1 {
	status = "okay";
};

&u2phy1_otg {
	rockchip,typec-vbus-det;
	status = "okay";
};

&usbdp_phy1 {
	status = "okay";
};

&usbdp_phy1_u3 {
	status = "okay";
};

&usbdrd3_1 {
	status = "okay";
};

&usbdrd_dwc3_1 {
	status = "okay";
	dr_mode = "host";
};

&vop {
	status = "okay";
};

&vop_mmu {
	status = "okay";
};

&vp0 {
	rockchip,plane-mask = <(1 << ROCKCHIP_VOP2_CLUSTER0 | 1 << ROCKCHIP_VOP2_ESMART0)>;
	rockchip,primary-plane = <ROCKCHIP_VOP2_CLUSTER0>;
	cursor-win-id = <ROCKCHIP_VOP2_ESMART0>;
};

&vp1 {
	rockchip,plane-mask = <(1 << ROCKCHIP_VOP2_CLUSTER1 | 1 << ROCKCHIP_VOP2_ESMART1)>;
	rockchip,primary-plane = <ROCKCHIP_VOP2_CLUSTER1>;
	cursor-win-id = <ROCKCHIP_VOP2_ESMART1>;
};

&vp2 {
	rockchip,plane-mask = <(1 << ROCKCHIP_VOP2_CLUSTER2 | 1 << ROCKCHIP_VOP2_ESMART2)>;
	rockchip,primary-plane = <ROCKCHIP_VOP2_CLUSTER2>;
	cursor-win-id = <ROCKCHIP_VOP2_ESMART2>;
};

&vp3 {
	rockchip,plane-mask = <(1 << ROCKCHIP_VOP2_CLUSTER3 | 1 << ROCKCHIP_VOP2_ESMART3)>;
	rockchip,primary-plane = <ROCKCHIP_VOP2_CLUSTER3>;
	cursor-win-id = <ROCKCHIP_VOP2_ESMART3>;
};

&avdd_0v75_s0 {
	regulator-state-mem {
		regulator-on-in-suspend;
		regulator-suspend-microvolt = <837500>;
	};
};

&avcc_1v8_s0 {
	regulator-state-mem {
		regulator-on-in-suspend;
		regulator-suspend-microvolt = <1800000>;
	};
};

&vcc_1v8_s0 {
	regulator-state-mem {
		regulator-on-in-suspend;
		regulator-suspend-microvolt = <1800000>;
	};
};

&vcc_3v3_s0 {
	regulator-state-mem {
		regulator-on-in-suspend;
		regulator-suspend-microvolt = <3300000>;
	};
};

&vdd_log_s0 {
	regulator-state-mem {
		regulator-on-in-suspend;
		regulator-suspend-microvolt = <750000>;
	};
};

&vdd_ddr_pll_s0 {
	regulator-state-mem {
		regulator-on-in-suspend;
		regulator-suspend-microvolt = <850000>;
	};
};


&pinctrl {

	csi {
		cam3_pwr: cam3-pwr {
			rockchip,pins =
				<3 RK_PC1 RK_FUNC_GPIO &pcfg_pull_none>;	/* CAM3_PWREN */
		};

		cam4_pwr: cam4-pwr {
			rockchip,pins =
				<3 RK_PC2 RK_FUNC_GPIO &pcfg_pull_none>;	/* CAM4_PWR_EN */
		};
	};
	dp {
		dp0_tx1_hpd: dp0-hpd {
			rockchip,pins =
				<2 RK_PC1 RK_FUNC_GPIO &pcfg_pull_none>;
		};
	};
	exp {
		exp_pins: exp-pins {
			rockchip,pins =
				<1 RK_PA7 RK_FUNC_GPIO &pcfg_pull_none>;	/* GPIO_EXP_INT */
				// <3 RK_PD5 RK_FUNC_GPIO &pcfg_pull_up>;	/* GPIO_EXP_RESET */
		};
	};

	mux {
		mux_pins: mux-pins {
			rockchip,pins =
				<1 RK_PC6 RK_FUNC_GPIO &pcfg_pull_up>;		/* CAM_I2C_MUX_RST */
		};
	};

	pcie {
		pcie20_0_vcc_pins: pcie20-0-vcc-pins {
			rockchip,pins =
				<1 RK_PC0 RK_FUNC_GPIO &pcfg_pull_none>;	/* PCIE30_PWREN */
		};

		pcie20_1_vcc_pins: pcie20-1-vcc-pins {
			rockchip,pins =
				<1 RK_PC1 RK_FUNC_GPIO &pcfg_pull_none>;	/* PCIE30_PWREN */
		};

		pcie20x1_pins: pcie20x1-pins {
			rockchip,pins =
				/* pcie30x1_0_clkreqn_m2 */
				<1 RK_PB5 4 &pcfg_pull_none>,
				/* pcie30x1_0_perstn_m2 */
				<1 RK_PB4 4 &pcfg_pull_none>,
				/* pcie30x1_0_waken_m2 */
				<1 RK_PB3 4 &pcfg_pull_none>;
		};

		pcie30_clk_pins: pcie30-clk-pins {
			rockchip,pins =
				<4 RK_PA5 RK_FUNC_GPIO &pcfg_pull_none>;	/* PCIE30_CLK_PWREN */
		};

		pcie3x4_pins: pci3x4-pins {
			rockchip,pins =
				<1 RK_PB0 4 &pcfg_pull_none>,			/* pcie30x4_clkreqn_m3 */
				<1 RK_PB2 RK_FUNC_GPIO &pcfg_pull_none>,	/* pcie30x4_perstn_m3 */
				<1 RK_PB1 4 &pcfg_pull_none>;			/* pcie30x4_waken_m3 */
		};
	};
};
